# RN821X_RN721X_SOC_V2 register map
File version: v1.0.7
CPU: CM0 r0p0, little endian, no MPU, no FPU, 3 interrupt priority bits
Registers are 32-bit, read-write, reset 0x0 unless marked. A register's access mark holds for its fields unless they carry their own. Offsets are from the block's base; [hi:lo] are bit positions; {n}, {i} and the like mark numbered series.

## D2F — power energy calculation module
Base 0x4005C000
0x00 HFCONST4 — D2F00/03 high frequency pulse constant register configuration bits
  [15:0] HFCONST4
0x04 HFCONST5 — D2F01/04 high frequency pulse constant register configuration bits
  [15:0] HFCONST5
0x08 HFCONST6 — D2F02/05 high frequency pulse constant register configuration bits
  [15:0] HFCONST6
0x0C HFCONST7 — D2F06~11 high frequency pulse constant register configuration bits
  [15:0] HFCONST7
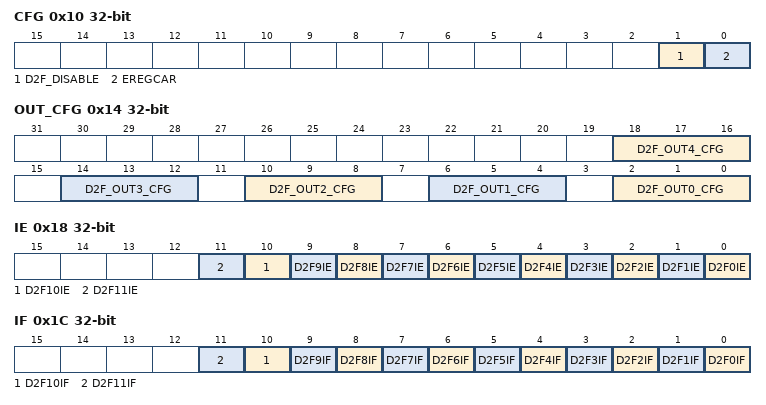
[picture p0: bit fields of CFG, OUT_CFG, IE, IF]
0x10 CFG — D2F config register
  [1] D2F_DISABLE — D2F module disable bit
  [0] EREGCAR — D2F energy register mode selection bit
    0=RC (D2F energy register select as clear after read); 1=ACC (D2F energy register select as accumulation mode)
0x14 OUT_CFG (reset mask 0x43210) — D2F output pulse config register
  [all] fields
    {v}=D2F{v:02} (select as D2F{v:02} pulse) (v=0..5)
  [4n+2:4n] D2F_OUT{n}_CFG (n=0..4) — D2F_OUT{n} d2f output pulse selection bits
0x18 IE — D2F interrupt enable register
  [all] fields
    0=DIS (disable); 1=EN (enable)
  [n] D2F{n}IE (n=0..11) — D2F{n:02} interrupt enable bit
0x1C IF — D2F interrupt flag register
  [all] fields
    0=NUL (interrupt occured); 1=OCC (interrupt not occured)
  [n] D2F{n}IF (n=0..11) — D2F{n:02} interrupt flag
0x20 D2FFCNT00 — D2F counter resistor No.00
  [15:0] D2FFCNT00 — D2F counter resistor No.00 bits
0x24 D2FFCNT01 — D2F counter resistor No.01
  [15:0] D2FFCNT01 — D2F counter resistor No.01 bits
0x28 D2FFCNT02 — D2F counter resistor No.02
  [15:0] D2FFCNT02 — D2F counter resistor No.02 bits
0x2C D2FFCNT03 — D2F counter resistor No.03
  [15:0] D2FFCNT03 — D2F counter resistor No.03 bits
0x30 D2FFCNT04 — D2F counter resistor No.04
  [15:0] D2FFCNT04 — D2F counter resistor No.04 bits
0x34 D2FFCNT05 — D2F counter resistor No.05
  [15:0] D2FFCNT05 — D2F counter resistor No.05 bits
0x38 D2FFCNT06 — D2F counter resistor No.06
  [15:0] D2FFCNT06 — D2F counter resistor No.06 bits
0x3C D2FFCNT07 — D2F counter resistor No.07
  [15:0] D2FFCNT07 — D2F counter resistor No.07 bits
0x40 D2FFCNT08 — D2F counter resistor No.08
  [15:0] D2FFCNT08 — D2F counter resistor No.08 bits
0x44 D2FFCNT09 — D2F counter resistor No.09
  [15:0] D2FFCNT09 — D2F counter resistor No.09 bits
0x48 D2FFCNT10 — D2F counter resistor No.10
  [15:0] D2FFCNT10 — D2F counter resistor No.10 bits
0x4C D2FFCNT11 — D2F counter resistor No.11
  [15:0] D2FFCNT11 — D2F counter resistor No.11 bits
0x50 D2FP00 — D2F power register No.00
  [31:0] D2FP00 — D2F power register No.00 bits
0x54 D2FP01 — D2F power register No.01
  [31:0] D2FP01 — D2F power register No.01 bits
0x58 D2FP02 — D2F power register No.02
  [31:0] D2FP02 — D2F power register No.02 bits
0x5C D2FP03 — D2F power register No.03
  [31:0] D2FP03 — D2F power register No.03 bits
0x60 D2FP04 — D2F power register No.04
  [31:0] D2FP04 — D2F power register No.04 bits
0x64 D2FP05 — D2F power register No.05
  [31:0] D2FP05 — D2F power register No.05 bits
0x68 D2FP06 — D2F power register No.06
  [31:0] D2FP06 — D2F power register No.06 bits
0x6C D2FP07 — D2F power register No.07
  [31:0] D2FP07 — D2F power register No.07 bits
0x70 D2FP08 — D2F power register No.08
  [31:0] D2FP08 — D2F power register No.08 bits
0x74 D2FP09 — D2F power register No.09
  [31:0] D2FP09 — D2F power register No.09 bits
0x78 D2FP10 — D2F power register No.10
  [31:0] D2FP10 — D2F power register No.10 bits
0x7C D2FP11 — D2F power register No.11
  [31:0] D2FP11 — D2F power register No.11 bits
0x80 D2FE00 ro — D2F energy register No.00
  [23:0] D2FE00 — D2F energy register No.00 bits
0x84 D2FE01 ro — D2F energy register No.01
  [23:0] D2FE01 — D2F energy register No.01 bits
0x88 D2FE02 ro — D2F energy register No.02
  [23:0] D2FE02 — D2F energy register No.02 bits
0x8C D2FE03 ro — D2F energy register No.03
  [23:0] D2FE03 — D2F energy register No.03 bits
0x90 D2FE04 ro — D2F energy register No.04
  [23:0] D2FE04 — D2F energy register No.04 bits
0x94 D2FE05 ro — D2F energy register No.05
  [23:0] D2FE05 — D2F energy register No.05 bits
0x98 D2FE06 ro — D2F energy register No.06
  [23:0] D2FE06 — D2F energy register No.06 bits
0x9C D2FE07 ro — D2F energy register No.07
  [23:0] D2FE07 — D2F energy register No.07 bits
0xA0 D2FE08 ro — D2F energy register No.08
  [23:0] D2FE08 — D2F energy register No.08 bits
0xA4 D2FE09 ro — D2F energy register No.09
  [23:0] D2FE09 — D2F energy register No.09 bits
0xA8 D2FE10 ro — D2F energy register No.10
  [23:0] D2FE10 — D2F energy register No.10 bits
0xAC D2FE11 ro — D2F energy register No.11
  [23:0] D2FE11 — D2F energy register No.11 bits
